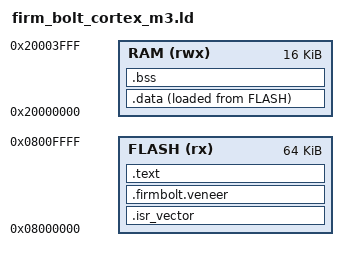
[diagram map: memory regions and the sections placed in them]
ENTRY(Reset_Handler)

MEMORY
{
  FLASH (rx)  : ORIGIN = 0x08000000, LENGTH = 64K
  RAM   (rwx) : ORIGIN = 0x20000000, LENGTH = 16K
}

SECTIONS
{
  .isr_vector ORIGIN(FLASH) :
  {
    KEEP(*(.isr_vector))
  } > FLASH

  /* Explicit typed capacity for Firm-BOLT external veneers.  No input section
     means no range is created for ordinary fixtures. */
  .firmbolt.veneer :
  {
    KEEP(*(.firmbolt.veneer))
  } > FLASH

  .text :
  {
    *(.text*)
    *(.rodata*)
  } > FLASH

  .data :
  {
    *(.data*)
  } > RAM AT > FLASH

  .bss (NOLOAD) :
  {
    *(.bss*)
    *(COMMON)
  } > RAM
}
